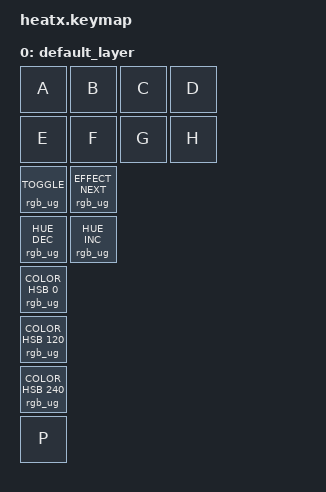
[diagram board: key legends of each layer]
#include <behaviors.dtsi>
#include <dt-bindings/zmk/keys.h>

/ {
    keymap {
        compatible = "zmk,keymap";

        default_layer {

            sensor-bindings = <
                &inc_dec_kp C_VOL_UP C_VOL_DN
            >;

            bindings = <
                &kp A                     &kp B                     &kp C                     &kp D
                &kp E                     &kp F                     &kp G                     &kp H

                &rgb_ug RGB_TOGGLE        &rgb_ug RGB_EFFECT_NEXT
                &rgb_ug RGB_HUE_DEC       &rgb_ug RGB_HUE_INC

                &rgb_ug RGB_COLOR_HSB 0   100 16
                &rgb_ug RGB_COLOR_HSB 120 100 16
                &rgb_ug RGB_COLOR_HSB 240 100 16
                &kp P
            >;
        };
    };
};
